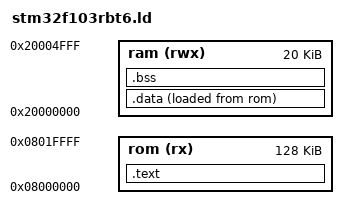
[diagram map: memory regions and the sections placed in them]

/* Linker script for STM32F103RBT6 */

MEMORY
{
	rom (rx) : ORIGIN = 0x08000000, LENGTH = 128K
	ram (rwx) : ORIGIN = 0x20000000, LENGTH = 20K
}

EXTERN(vector_table)
ENTRY(reset_handler)

SECTIONS
{
	.text : {
		*(.vectors)	/* Vector table */
		*(.text*)	/* Program code */
		. = ALIGN(4);
		*(.rodata*)	/* Read-only data */

		__ctors_start__ = .;
		KEEP(SORT(*)(.init_array)) /* static constructors */
		__ctors_end__ = .;

		. = ALIGN(4);
	} >rom

	. = ALIGN(4);
	_etext = .;

	.data : {
		_data = .;
		*(.data*)	/* Read-write initialized data */
		. = ALIGN(4);
		_edata = .;
	} >ram AT >rom
	_data_loadaddr = LOADADDR(.data);

	.bss : {
		*(.bss*)	/* Read-write zero initialized data */
		*(COMMON)
		. = ALIGN(4);
		_ebss = .;
	} >ram

	. = ALIGN(4);
	end = .;
}

PROVIDE(_stack = ORIGIN(ram) + LENGTH(ram));
